AUTOSAR XML (schema 00051)
package /Components
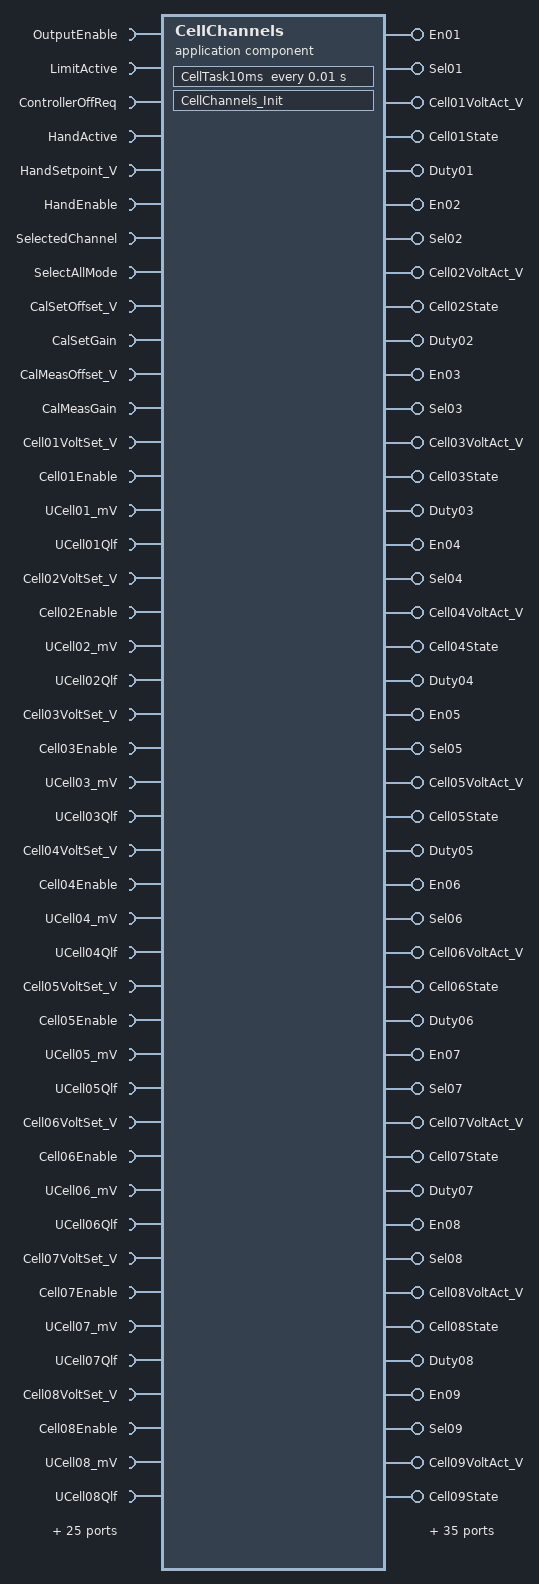
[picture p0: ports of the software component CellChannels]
  application sw component type CellChannels
    68 x require port:
      OutputEnable: nonqueued-receiver-com-spec{data-element=OutputEnable, init-value=0}, required-interface=OutputEnable
      LimitActive: nonqueued-receiver-com-spec{data-element=LimitActive, init-value=0}, required-interface=LimitActive
      ControllerOffReq: nonqueued-receiver-com-spec{data-element=ControllerOffReq, init-value=0}, required-interface=ControllerOffReq
      HandActive: nonqueued-receiver-com-spec{data-element=HandActive, init-value=0}, required-interface=HandActive
      HandSetpoint_V: nonqueued-receiver-com-spec{data-element=HandSetpoint_V, init-value=14 x 0}, required-interface=HandSetpoint_V
      HandEnable: nonqueued-receiver-com-spec{data-element=HandEnable, init-value=14 x 0}, required-interface=HandEnable
      SelectedChannel: nonqueued-receiver-com-spec{data-element=SelectedChannel, init-value=0}, required-interface=SelectedChannel
      SelectAllMode: nonqueued-receiver-com-spec{data-element=SelectAllMode, init-value=0}, required-interface=SelectAllMode
      CalSetOffset_V: nonqueued-receiver-com-spec{data-element=CalSetOffset_V, init-value=14 x 0}, required-interface=CalSetOffset_V
      CalSetGain: nonqueued-receiver-com-spec{data-element=CalSetGain, init-value=14 x 0}, required-interface=CalSetGain
      CalMeasOffset_V: nonqueued-receiver-com-spec{data-element=CalMeasOffset_V, init-value=14 x 0}, required-interface=CalMeasOffset_V
      CalMeasGain: nonqueued-receiver-com-spec{data-element=CalMeasGain, init-value=14 x 0}, required-interface=CalMeasGain
      Cell01VoltSet_V: nonqueued-receiver-com-spec{data-element=Cell01VoltSet_V, init-value=0}, required-interface=Cell01VoltSet_V
      Cell01Enable: nonqueued-receiver-com-spec{data-element=Cell01Enable, init-value=0}, required-interface=Cell01Enable
      UCell01_mV: nonqueued-receiver-com-spec{data-element=UCell01_mV, init-value=0}, required-interface=UCell01_mV
      UCell01Qlf: nonqueued-receiver-com-spec{data-element=UCell01Qlf, init-value=0}, required-interface=UCell01Qlf
      Cell02VoltSet_V: nonqueued-receiver-com-spec{data-element=Cell02VoltSet_V, init-value=0}, required-interface=Cell02VoltSet_V
      Cell02Enable: nonqueued-receiver-com-spec{data-element=Cell02Enable, init-value=0}, required-interface=Cell02Enable
      UCell02_mV: nonqueued-receiver-com-spec{data-element=UCell02_mV, init-value=0}, required-interface=UCell02_mV
      UCell02Qlf: nonqueued-receiver-com-spec{data-element=UCell02Qlf, init-value=0}, required-interface=UCell02Qlf
      Cell03VoltSet_V: nonqueued-receiver-com-spec{data-element=Cell03VoltSet_V, init-value=0}, required-interface=Cell03VoltSet_V
      Cell03Enable: nonqueued-receiver-com-spec{data-element=Cell03Enable, init-value=0}, required-interface=Cell03Enable
      UCell03_mV: nonqueued-receiver-com-spec{data-element=UCell03_mV, init-value=0}, required-interface=UCell03_mV
      UCell03Qlf: nonqueued-receiver-com-spec{data-element=UCell03Qlf, init-value=0}, required-interface=UCell03Qlf
      Cell04VoltSet_V: nonqueued-receiver-com-spec{data-element=Cell04VoltSet_V, init-value=0}, required-interface=Cell04VoltSet_V
      Cell04Enable: nonqueued-receiver-com-spec{data-element=Cell04Enable, init-value=0}, required-interface=Cell04Enable
      UCell04_mV: nonqueued-receiver-com-spec{data-element=UCell04_mV, init-value=0}, required-interface=UCell04_mV
      UCell04Qlf: nonqueued-receiver-com-spec{data-element=UCell04Qlf, init-value=0}, required-interface=UCell04Qlf
      Cell05VoltSet_V: nonqueued-receiver-com-spec{data-element=Cell05VoltSet_V, init-value=0}, required-interface=Cell05VoltSet_V
      Cell05Enable: nonqueued-receiver-com-spec{data-element=Cell05Enable, init-value=0}, required-interface=Cell05Enable
      UCell05_mV: nonqueued-receiver-com-spec{data-element=UCell05_mV, init-value=0}, required-interface=UCell05_mV
      UCell05Qlf: nonqueued-receiver-com-spec{data-element=UCell05Qlf, init-value=0}, required-interface=UCell05Qlf
      Cell06VoltSet_V: nonqueued-receiver-com-spec{data-element=Cell06VoltSet_V, init-value=0}, required-interface=Cell06VoltSet_V
      Cell06Enable: nonqueued-receiver-com-spec{data-element=Cell06Enable, init-value=0}, required-interface=Cell06Enable
      UCell06_mV: nonqueued-receiver-com-spec{data-element=UCell06_mV, init-value=0}, required-interface=UCell06_mV
      UCell06Qlf: nonqueued-receiver-com-spec{data-element=UCell06Qlf, init-value=0}, required-interface=UCell06Qlf
      Cell07VoltSet_V: nonqueued-receiver-com-spec{data-element=Cell07VoltSet_V, init-value=0}, required-interface=Cell07VoltSet_V
      Cell07Enable: nonqueued-receiver-com-spec{data-element=Cell07Enable, init-value=0}, required-interface=Cell07Enable
      UCell07_mV: nonqueued-receiver-com-spec{data-element=UCell07_mV, init-value=0}, required-interface=UCell07_mV
      UCell07Qlf: nonqueued-receiver-com-spec{data-element=UCell07Qlf, init-value=0}, required-interface=UCell07Qlf
      Cell08VoltSet_V: nonqueued-receiver-com-spec{data-element=Cell08VoltSet_V, init-value=0}, required-interface=Cell08VoltSet_V
      Cell08Enable: nonqueued-receiver-com-spec{data-element=Cell08Enable, init-value=0}, required-interface=Cell08Enable
      UCell08_mV: nonqueued-receiver-com-spec{data-element=UCell08_mV, init-value=0}, required-interface=UCell08_mV
      UCell08Qlf: nonqueued-receiver-com-spec{data-element=UCell08Qlf, init-value=0}, required-interface=UCell08Qlf
      Cell09VoltSet_V: nonqueued-receiver-com-spec{data-element=Cell09VoltSet_V, init-value=0}, required-interface=Cell09VoltSet_V
      Cell09Enable: nonqueued-receiver-com-spec{data-element=Cell09Enable, init-value=0}, required-interface=Cell09Enable
      UCell09_mV: nonqueued-receiver-com-spec{data-element=UCell09_mV, init-value=0}, required-interface=UCell09_mV
      UCell09Qlf: nonqueued-receiver-com-spec{data-element=UCell09Qlf, init-value=0}, required-interface=UCell09Qlf
      Cell10VoltSet_V: nonqueued-receiver-com-spec{data-element=Cell10VoltSet_V, init-value=0}, required-interface=Cell10VoltSet_V
      Cell10Enable: nonqueued-receiver-com-spec{data-element=Cell10Enable, init-value=0}, required-interface=Cell10Enable
      UCell10_mV: nonqueued-receiver-com-spec{data-element=UCell10_mV, init-value=0}, required-interface=UCell10_mV
      UCell10Qlf: nonqueued-receiver-com-spec{data-element=UCell10Qlf, init-value=0}, required-interface=UCell10Qlf
      Cell11VoltSet_V: nonqueued-receiver-com-spec{data-element=Cell11VoltSet_V, init-value=0}, required-interface=Cell11VoltSet_V
      Cell11Enable: nonqueued-receiver-com-spec{data-element=Cell11Enable, init-value=0}, required-interface=Cell11Enable
      UCell11_mV: nonqueued-receiver-com-spec{data-element=UCell11_mV, init-value=0}, required-interface=UCell11_mV
      UCell11Qlf: nonqueued-receiver-com-spec{data-element=UCell11Qlf, init-value=0}, required-interface=UCell11Qlf
      Cell12VoltSet_V: nonqueued-receiver-com-spec{data-element=Cell12VoltSet_V, init-value=0}, required-interface=Cell12VoltSet_V
      Cell12Enable: nonqueued-receiver-com-spec{data-element=Cell12Enable, init-value=0}, required-interface=Cell12Enable
      UCell12_mV: nonqueued-receiver-com-spec{data-element=UCell12_mV, init-value=0}, required-interface=UCell12_mV
      UCell12Qlf: nonqueued-receiver-com-spec{data-element=UCell12Qlf, init-value=0}, required-interface=UCell12Qlf
      Cell13VoltSet_V: nonqueued-receiver-com-spec{data-element=Cell13VoltSet_V, init-value=0}, required-interface=Cell13VoltSet_V
      Cell13Enable: nonqueued-receiver-com-spec{data-element=Cell13Enable, init-value=0}, required-interface=Cell13Enable
      UCell13_mV: nonqueued-receiver-com-spec{data-element=UCell13_mV, init-value=0}, required-interface=UCell13_mV
      UCell13Qlf: nonqueued-receiver-com-spec{data-element=UCell13Qlf, init-value=0}, required-interface=UCell13Qlf
      Cell14VoltSet_V: nonqueued-receiver-com-spec{data-element=Cell14VoltSet_V, init-value=0}, required-interface=Cell14VoltSet_V
      Cell14Enable: nonqueued-receiver-com-spec{data-element=Cell14Enable, init-value=0}, required-interface=Cell14Enable
      UCell14_mV: nonqueued-receiver-com-spec{data-element=UCell14_mV, init-value=0}, required-interface=UCell14_mV
      UCell14Qlf: nonqueued-receiver-com-spec{data-element=UCell14Qlf, init-value=0}, required-interface=UCell14Qlf
    79 x provide port:
      En01: nonqueued-sender-com-spec{data-element=En01, init-value=0}, provided-interface=En01
      Sel01: nonqueued-sender-com-spec{data-element=Sel01, init-value=0}, provided-interface=Sel01
      Cell01VoltAct_V: nonqueued-sender-com-spec{data-element=Cell01VoltAct_V, init-value=0}, provided-interface=Cell01VoltAct_V
      Cell01State: nonqueued-sender-com-spec{data-element=Cell01State, init-value=0}, provided-interface=Cell01State
      Duty01: nonqueued-sender-com-spec{data-element=Duty01, init-value=0}, provided-interface=Duty01
      En02: nonqueued-sender-com-spec{data-element=En02, init-value=0}, provided-interface=En02
      Sel02: nonqueued-sender-com-spec{data-element=Sel02, init-value=0}, provided-interface=Sel02
      Cell02VoltAct_V: nonqueued-sender-com-spec{data-element=Cell02VoltAct_V, init-value=0}, provided-interface=Cell02VoltAct_V
      Cell02State: nonqueued-sender-com-spec{data-element=Cell02State, init-value=0}, provided-interface=Cell02State
      Duty02: nonqueued-sender-com-spec{data-element=Duty02, init-value=0}, provided-interface=Duty02
      En03: nonqueued-sender-com-spec{data-element=En03, init-value=0}, provided-interface=En03
      Sel03: nonqueued-sender-com-spec{data-element=Sel03, init-value=0}, provided-interface=Sel03
      Cell03VoltAct_V: nonqueued-sender-com-spec{data-element=Cell03VoltAct_V, init-value=0}, provided-interface=Cell03VoltAct_V
      Cell03State: nonqueued-sender-com-spec{data-element=Cell03State, init-value=0}, provided-interface=Cell03State
      Duty03: nonqueued-sender-com-spec{data-element=Duty03, init-value=0}, provided-interface=Duty03
      En04: nonqueued-sender-com-spec{data-element=En04, init-value=0}, provided-interface=En04
      Sel04: nonqueued-sender-com-spec{data-element=Sel04, init-value=0}, provided-interface=Sel04
      Cell04VoltAct_V: nonqueued-sender-com-spec{data-element=Cell04VoltAct_V, init-value=0}, provided-interface=Cell04VoltAct_V
      Cell04State: nonqueued-sender-com-spec{data-element=Cell04State, init-value=0}, provided-interface=Cell04State
      Duty04: nonqueued-sender-com-spec{data-element=Duty04, init-value=0}, provided-interface=Duty04
      En05: nonqueued-sender-com-spec{data-element=En05, init-value=0}, provided-interface=En05
      Sel05: nonqueued-sender-com-spec{data-element=Sel05, init-value=0}, provided-interface=Sel05
      Cell05VoltAct_V: nonqueued-sender-com-spec{data-element=Cell05VoltAct_V, init-value=0}, provided-interface=Cell05VoltAct_V
      Cell05State: nonqueued-sender-com-spec{data-element=Cell05State, init-value=0}, provided-interface=Cell05State
      Duty05: nonqueued-sender-com-spec{data-element=Duty05, init-value=0}, provided-interface=Duty05
      En06: nonqueued-sender-com-spec{data-element=En06, init-value=0}, provided-interface=En06
      Sel06: nonqueued-sender-com-spec{data-element=Sel06, init-value=0}, provided-interface=Sel06
      Cell06VoltAct_V: nonqueued-sender-com-spec{data-element=Cell06VoltAct_V, init-value=0}, provided-interface=Cell06VoltAct_V
      Cell06State: nonqueued-sender-com-spec{data-element=Cell06State, init-value=0}, provided-interface=Cell06State
      Duty06: nonqueued-sender-com-spec{data-element=Duty06, init-value=0}, provided-interface=Duty06
      En07: nonqueued-sender-com-spec{data-element=En07, init-value=0}, provided-interface=En07
      Sel07: nonqueued-sender-com-spec{data-element=Sel07, init-value=0}, provided-interface=Sel07
      Cell07VoltAct_V: nonqueued-sender-com-spec{data-element=Cell07VoltAct_V, init-value=0}, provided-interface=Cell07VoltAct_V
      Cell07State: nonqueued-sender-com-spec{data-element=Cell07State, init-value=0}, provided-interface=Cell07State
      Duty07: nonqueued-sender-com-spec{data-element=Duty07, init-value=0}, provided-interface=Duty07
      En08: nonqueued-sender-com-spec{data-element=En08, init-value=0}, provided-interface=En08
      Sel08: nonqueued-sender-com-spec{data-element=Sel08, init-value=0}, provided-interface=Sel08
      Cell08VoltAct_V: nonqueued-sender-com-spec{data-element=Cell08VoltAct_V, init-value=0}, provided-interface=Cell08VoltAct_V
      Cell08State: nonqueued-sender-com-spec{data-element=Cell08State, init-value=0}, provided-interface=Cell08State
      Duty08: nonqueued-sender-com-spec{data-element=Duty08, init-value=0}, provided-interface=Duty08
      En09: nonqueued-sender-com-spec{data-element=En09, init-value=0}, provided-interface=En09
      Sel09: nonqueued-sender-com-spec{data-element=Sel09, init-value=0}, provided-interface=Sel09
      Cell09VoltAct_V: nonqueued-sender-com-spec{data-element=Cell09VoltAct_V, init-value=0}, provided-interface=Cell09VoltAct_V
      Cell09State: nonqueued-sender-com-spec{data-element=Cell09State, init-value=0}, provided-interface=Cell09State
      Duty09: nonqueued-sender-com-spec{data-element=Duty09, init-value=0}, provided-interface=Duty09
      En10: nonqueued-sender-com-spec{data-element=En10, init-value=0}, provided-interface=En10
      Sel10: nonqueued-sender-com-spec{data-element=Sel10, init-value=0}, provided-interface=Sel10
      Cell10VoltAct_V: nonqueued-sender-com-spec{data-element=Cell10VoltAct_V, init-value=0}, provided-interface=Cell10VoltAct_V
      Cell10State: nonqueued-sender-com-spec{data-element=Cell10State, init-value=0}, provided-interface=Cell10State
      Duty10: nonqueued-sender-com-spec{data-element=Duty10, init-value=0}, provided-interface=Duty10
      En11: nonqueued-sender-com-spec{data-element=En11, init-value=0}, provided-interface=En11
      Sel11: nonqueued-sender-com-spec{data-element=Sel11, init-value=0}, provided-interface=Sel11
      Cell11VoltAct_V: nonqueued-sender-com-spec{data-element=Cell11VoltAct_V, init-value=0}, provided-interface=Cell11VoltAct_V
      Cell11State: nonqueued-sender-com-spec{data-element=Cell11State, init-value=0}, provided-interface=Cell11State
      Duty11: nonqueued-sender-com-spec{data-element=Duty11, init-value=0}, provided-interface=Duty11
      En12: nonqueued-sender-com-spec{data-element=En12, init-value=0}, provided-interface=En12
      Sel12: nonqueued-sender-com-spec{data-element=Sel12, init-value=0}, provided-interface=Sel12
      Cell12VoltAct_V: nonqueued-sender-com-spec{data-element=Cell12VoltAct_V, init-value=0}, provided-interface=Cell12VoltAct_V
      Cell12State: nonqueued-sender-com-spec{data-element=Cell12State, init-value=0}, provided-interface=Cell12State
      Duty12: nonqueued-sender-com-spec{data-element=Duty12, init-value=0}, provided-interface=Duty12
      En13: nonqueued-sender-com-spec{data-element=En13, init-value=0}, provided-interface=En13
      Sel13: nonqueued-sender-com-spec{data-element=Sel13, init-value=0}, provided-interface=Sel13
      Cell13VoltAct_V: nonqueued-sender-com-spec{data-element=Cell13VoltAct_V, init-value=0}, provided-interface=Cell13VoltAct_V
      Cell13State: nonqueued-sender-com-spec{data-element=Cell13State, init-value=0}, provided-interface=Cell13State
      Duty13: nonqueued-sender-com-spec{data-element=Duty13, init-value=0}, provided-interface=Duty13
      En14: nonqueued-sender-com-spec{data-element=En14, init-value=0}, provided-interface=En14
      Sel14: nonqueued-sender-com-spec{data-element=Sel14, init-value=0}, provided-interface=Sel14
      Cell14VoltAct_V: nonqueued-sender-com-spec{data-element=Cell14VoltAct_V, init-value=0}, provided-interface=Cell14VoltAct_V
      Cell14State: nonqueued-sender-com-spec{data-element=Cell14State, init-value=0}, provided-interface=Cell14State
      Duty14: nonqueued-sender-com-spec{data-element=Duty14, init-value=0}, provided-interface=Duty14
      ActualVolt_V: nonqueued-sender-com-spec{data-element=ActualVolt_V, init-value=14 x 0}, provided-interface=ActualVolt_V
      ControllerOn: nonqueued-sender-com-spec{data-element=ControllerOn, init-value=0}, provided-interface=ControllerOn
      ControllerOffAct: nonqueued-sender-com-spec{data-element=ControllerOffAct, init-value=0}, provided-interface=ControllerOffAct
      ChannelsReleased: nonqueued-sender-com-spec{data-element=ChannelsReleased, init-value=0}, provided-interface=ChannelsReleased
      OverVoltage: nonqueued-sender-com-spec{data-element=OverVoltage, init-value=0}, provided-interface=OverVoltage
      Cell15State: nonqueued-sender-com-spec{data-element=Cell15State, init-value=0}, provided-interface=Cell15State
      Cell15VoltAct_V: nonqueued-sender-com-spec{data-element=Cell15VoltAct_V, init-value=0}, provided-interface=Cell15VoltAct_V
      Cell16State: nonqueued-sender-com-spec{data-element=Cell16State, init-value=0}, provided-interface=Cell16State
      Cell16VoltAct_V: nonqueued-sender-com-spec{data-element=Cell16VoltAct_V, init-value=0}, provided-interface=Cell16VoltAct_V
    require port CalPrm: required-interface=CalPrm
      required-com-specs:
        init-value=CalPrm_CtrlKi_per_s:1, parameter=CtrlKi_per_s
        init-value=CalPrm_CtrlKp:0.2, parameter=CtrlKp
        init-value=CalPrm_CtrlLimit_V:0.1, parameter=CtrlLimit_V
        init-value=CalPrm_OutputFloor_V:0.7, parameter=OutputFloor_V
        init-value=CalPrm_OverVoltThd_V:0.2, parameter=OverVoltThd_V
        init-value=CalPrm_SetpointLimit_V:5, parameter=SetpointLimit_V
        init-value=CalPrm_StepThreshold_V:0.2, parameter=StepThreshold_V
        init-value=CalPrm_VoltageSenseFilter:0.1, parameter=VoltageSenseFilter
        init-value=CalPrm_VoltageSenseMeas_Ax:[CalPrm_VoltageSenseMeas_Ax_rt_Array_float32_6_1:0, CalPrm_VoltageSenseMeas_Ax_rt_Array_float32_6_2:398.1, CalPrm_VoltageSenseMeas_Ax_rt_Array_float32_6_3:795.7, CalPrm_VoltageSenseMeas_Ax_rt_Array_float32_6_4:1195.8, CalPrm_VoltageSenseMeas_Ax_rt_Array_float32_6_5:1596.4, CalPrm_VoltageSenseMeas_Ax_rt_Array_float32_6_6:1996], parameter=VoltageSenseMeas_Ax
        init-value=CalPrm_VoltageSenseValue_T:[CalPrm_VoltageSenseValue_T_rt_Array_float32_6_1:0, CalPrm_VoltageSenseValue_T_rt_Array_float32_6_2:1, CalPrm_VoltageSenseValue_T_rt_Array_float32_6_3:2, CalPrm_VoltageSenseValue_T_rt_Array_float32_6_4:3, CalPrm_VoltageSenseValue_T_rt_Array_float32_6_5:4, CalPrm_VoltageSenseValue_T_rt_Array_float32_6_6:5], parameter=VoltageSenseValue_T
        init-value=CalPrm_VoltageSetPwm_T:[CalPrm_VoltageSetPwm_T_rt_Array_float32_6_1:0, CalPrm_VoltageSetPwm_T_rt_Array_float32_6_2:0.185875, CalPrm_VoltageSetPwm_T_rt_Array_float32_6_3:0.378085, CalPrm_VoltageSetPwm_T_rt_Array_float32_6_4:0.570892, CalPrm_VoltageSetPwm_T_rt_Array_float32_6_5:0.763797, CalPrm_VoltageSetPwm_T_rt_Array_float32_6_6:0.9566], parameter=VoltageSetPwm_T
        init-value=CalPrm_VoltageSetValue_Ax:[CalPrm_VoltageSetValue_Ax_rt_Array_float32_6_1:0, CalPrm_VoltageSetValue_Ax_rt_Array_float32_6_2:1, CalPrm_VoltageSetValue_Ax_rt_Array_float32_6_3:2, CalPrm_VoltageSetValue_Ax_rt_Array_float32_6_4:3, CalPrm_VoltageSetValue_Ax_rt_Array_float32_6_5:4, CalPrm_VoltageSetValue_Ax_rt_Array_float32_6_6:5], parameter=VoltageSetValue_Ax
        init-value=CalPrm_OverVoltTime_cycles:10, parameter=OverVoltTime_cycles
        init-value=CalPrm_StepHold_cycles:50, parameter=StepHold_cycles
    behavior CellChannels_IB: handle-termination-and-restart=NO-SUPPORT
      timing event Event_CellTask10ms: start-on-event=CellTask10ms, period=0.01
      runnable CellChannels_Init
        data-send-points:
          access OUT_Cell15State_Cell15State: accessed-variable=Cell15State.Cell15State
          access OUT_Cell16State_Cell16State: accessed-variable=Cell16State.Cell16State
      runnable CellTask10ms
        data-receive-point-by-arguments:
          68 x access:
            IN_CalMeasGain_CalMeasGain: accessed-variable=CalMeasGain.CalMeasGain
            IN_CalMeasOffset_V_CalMeasOffset_V: accessed-variable=CalMeasOffset_V.CalMeasOffset_V
            IN_CalSetGain_CalSetGain: accessed-variable=CalSetGain.CalSetGain
            IN_CalSetOffset_V_CalSetOffset_V: accessed-variable=CalSetOffset_V.CalSetOffset_V
            IN_Cell01Enable_Cell01Enable: accessed-variable=Cell01Enable.Cell01Enable
            IN_Cell01VoltSet_V_Cell01VoltSet_V: accessed-variable=Cell01VoltSet_V.Cell01VoltSet_V
            IN_Cell02Enable_Cell02Enable: accessed-variable=Cell02Enable.Cell02Enable
            IN_Cell02VoltSet_V_Cell02VoltSet_V: accessed-variable=Cell02VoltSet_V.Cell02VoltSet_V
            IN_Cell03Enable_Cell03Enable: accessed-variable=Cell03Enable.Cell03Enable
            IN_Cell03VoltSet_V_Cell03VoltSet_V: accessed-variable=Cell03VoltSet_V.Cell03VoltSet_V
            IN_Cell04Enable_Cell04Enable: accessed-variable=Cell04Enable.Cell04Enable
            IN_Cell04VoltSet_V_Cell04VoltSet_V: accessed-variable=Cell04VoltSet_V.Cell04VoltSet_V
            IN_Cell05Enable_Cell05Enable: accessed-variable=Cell05Enable.Cell05Enable
            IN_Cell05VoltSet_V_Cell05VoltSet_V: accessed-variable=Cell05VoltSet_V.Cell05VoltSet_V
            IN_Cell06Enable_Cell06Enable: accessed-variable=Cell06Enable.Cell06Enable
            IN_Cell06VoltSet_V_Cell06VoltSet_V: accessed-variable=Cell06VoltSet_V.Cell06VoltSet_V
            IN_Cell07Enable_Cell07Enable: accessed-variable=Cell07Enable.Cell07Enable
            IN_Cell07VoltSet_V_Cell07VoltSet_V: accessed-variable=Cell07VoltSet_V.Cell07VoltSet_V
            IN_Cell08Enable_Cell08Enable: accessed-variable=Cell08Enable.Cell08Enable
            IN_Cell08VoltSet_V_Cell08VoltSet_V: accessed-variable=Cell08VoltSet_V.Cell08VoltSet_V
            IN_Cell09Enable_Cell09Enable: accessed-variable=Cell09Enable.Cell09Enable
            IN_Cell09VoltSet_V_Cell09VoltSet_V: accessed-variable=Cell09VoltSet_V.Cell09VoltSet_V
            IN_Cell10Enable_Cell10Enable: accessed-variable=Cell10Enable.Cell10Enable
            IN_Cell10VoltSet_V_Cell10VoltSet_V: accessed-variable=Cell10VoltSet_V.Cell10VoltSet_V
            IN_Cell11Enable_Cell11Enable: accessed-variable=Cell11Enable.Cell11Enable
            IN_Cell11VoltSet_V_Cell11VoltSet_V: accessed-variable=Cell11VoltSet_V.Cell11VoltSet_V
            IN_Cell12Enable_Cell12Enable: accessed-variable=Cell12Enable.Cell12Enable
            IN_Cell12VoltSet_V_Cell12VoltSet_V: accessed-variable=Cell12VoltSet_V.Cell12VoltSet_V
            IN_Cell13Enable_Cell13Enable: accessed-variable=Cell13Enable.Cell13Enable
            IN_Cell13VoltSet_V_Cell13VoltSet_V: accessed-variable=Cell13VoltSet_V.Cell13VoltSet_V
            IN_Cell14Enable_Cell14Enable: accessed-variable=Cell14Enable.Cell14Enable
            IN_Cell14VoltSet_V_Cell14VoltSet_V: accessed-variable=Cell14VoltSet_V.Cell14VoltSet_V
            IN_ControllerOffReq_ControllerOffReq: accessed-variable=ControllerOffReq.ControllerOffReq
            IN_HandActive_HandActive: accessed-variable=HandActive.HandActive
            IN_HandEnable_HandEnable: accessed-variable=HandEnable.HandEnable
            IN_HandSetpoint_V_HandSetpoint_V: accessed-variable=HandSetpoint_V.HandSetpoint_V
            IN_LimitActive_LimitActive: accessed-variable=LimitActive.LimitActive
            IN_OutputEnable_OutputEnable: accessed-variable=OutputEnable.OutputEnable
            IN_SelectAllMode_SelectAllMode: accessed-variable=SelectAllMode.SelectAllMode
            IN_SelectedChannel_SelectedChannel: accessed-variable=SelectedChannel.SelectedChannel
            IN_UCell01Qlf_UCell01Qlf: accessed-variable=UCell01Qlf.UCell01Qlf
            IN_UCell01_mV_UCell01_mV: accessed-variable=UCell01_mV.UCell01_mV
            IN_UCell02Qlf_UCell02Qlf: accessed-variable=UCell02Qlf.UCell02Qlf
            IN_UCell02_mV_UCell02_mV: accessed-variable=UCell02_mV.UCell02_mV
            IN_UCell03Qlf_UCell03Qlf: accessed-variable=UCell03Qlf.UCell03Qlf
            IN_UCell03_mV_UCell03_mV: accessed-variable=UCell03_mV.UCell03_mV
            IN_UCell04Qlf_UCell04Qlf: accessed-variable=UCell04Qlf.UCell04Qlf
            IN_UCell04_mV_UCell04_mV: accessed-variable=UCell04_mV.UCell04_mV
            IN_UCell05Qlf_UCell05Qlf: accessed-variable=UCell05Qlf.UCell05Qlf
            IN_UCell05_mV_UCell05_mV: accessed-variable=UCell05_mV.UCell05_mV
            IN_UCell06Qlf_UCell06Qlf: accessed-variable=UCell06Qlf.UCell06Qlf
            IN_UCell06_mV_UCell06_mV: accessed-variable=UCell06_mV.UCell06_mV
            IN_UCell07Qlf_UCell07Qlf: accessed-variable=UCell07Qlf.UCell07Qlf
            IN_UCell07_mV_UCell07_mV: accessed-variable=UCell07_mV.UCell07_mV
            IN_UCell08Qlf_UCell08Qlf: accessed-variable=UCell08Qlf.UCell08Qlf
            IN_UCell08_mV_UCell08_mV: accessed-variable=UCell08_mV.UCell08_mV
            IN_UCell09Qlf_UCell09Qlf: accessed-variable=UCell09Qlf.UCell09Qlf
            IN_UCell09_mV_UCell09_mV: accessed-variable=UCell09_mV.UCell09_mV
            IN_UCell10Qlf_UCell10Qlf: accessed-variable=UCell10Qlf.UCell10Qlf
            IN_UCell10_mV_UCell10_mV: accessed-variable=UCell10_mV.UCell10_mV
            IN_UCell11Qlf_UCell11Qlf: accessed-variable=UCell11Qlf.UCell11Qlf
            IN_UCell11_mV_UCell11_mV: accessed-variable=UCell11_mV.UCell11_mV
            IN_UCell12Qlf_UCell12Qlf: accessed-variable=UCell12Qlf.UCell12Qlf
            IN_UCell12_mV_UCell12_mV: accessed-variable=UCell12_mV.UCell12_mV
            IN_UCell13Qlf_UCell13Qlf: accessed-variable=UCell13Qlf.UCell13Qlf
            IN_UCell13_mV_UCell13_mV: accessed-variable=UCell13_mV.UCell13_mV
            IN_UCell14Qlf_UCell14Qlf: accessed-variable=UCell14Qlf.UCell14Qlf
            IN_UCell14_mV_UCell14_mV: accessed-variable=UCell14_mV.UCell14_mV
        data-send-points:
          79 x access:
            OUT_En01_En01: accessed-variable=En01.En01
            OUT_Sel01_Sel01: accessed-variable=Sel01.Sel01
            OUT_Cell01VoltAct_V_Cell01VoltAct_V: accessed-variable=Cell01VoltAct_V.Cell01VoltAct_V
            OUT_Cell01State_Cell01State: accessed-variable=Cell01State.Cell01State
            OUT_Duty01_Duty01: accessed-variable=Duty01.Duty01
            OUT_En02_En02: accessed-variable=En02.En02
            OUT_Sel02_Sel02: accessed-variable=Sel02.Sel02
            OUT_Cell02VoltAct_V_Cell02VoltAct_V: accessed-variable=Cell02VoltAct_V.Cell02VoltAct_V
            OUT_Cell02State_Cell02State: accessed-variable=Cell02State.Cell02State
            OUT_Duty02_Duty02: accessed-variable=Duty02.Duty02
            OUT_En03_En03: accessed-variable=En03.En03
            OUT_Sel03_Sel03: accessed-variable=Sel03.Sel03
            OUT_Cell03VoltAct_V_Cell03VoltAct_V: accessed-variable=Cell03VoltAct_V.Cell03VoltAct_V
            OUT_Cell03State_Cell03State: accessed-variable=Cell03State.Cell03State
            OUT_Duty03_Duty03: accessed-variable=Duty03.Duty03
            OUT_En04_En04: accessed-variable=En04.En04
            OUT_Sel04_Sel04: accessed-variable=Sel04.Sel04
            OUT_Cell04VoltAct_V_Cell04VoltAct_V: accessed-variable=Cell04VoltAct_V.Cell04VoltAct_V
            OUT_Cell04State_Cell04State: accessed-variable=Cell04State.Cell04State
            OUT_Duty04_Duty04: accessed-variable=Duty04.Duty04
            OUT_En05_En05: accessed-variable=En05.En05
            OUT_Sel05_Sel05: accessed-variable=Sel05.Sel05
            OUT_Cell05VoltAct_V_Cell05VoltAct_V: accessed-variable=Cell05VoltAct_V.Cell05VoltAct_V
            OUT_Cell05State_Cell05State: accessed-variable=Cell05State.Cell05State
            OUT_Duty05_Duty05: accessed-variable=Duty05.Duty05
            OUT_En06_En06: accessed-variable=En06.En06
            OUT_Sel06_Sel06: accessed-variable=Sel06.Sel06
            OUT_Cell06VoltAct_V_Cell06VoltAct_V: accessed-variable=Cell06VoltAct_V.Cell06VoltAct_V
            OUT_Cell06State_Cell06State: accessed-variable=Cell06State.Cell06State
            OUT_Duty06_Duty06: accessed-variable=Duty06.Duty06
            OUT_En07_En07: accessed-variable=En07.En07
            OUT_Sel07_Sel07: accessed-variable=Sel07.Sel07
            OUT_Cell07VoltAct_V_Cell07VoltAct_V: accessed-variable=Cell07VoltAct_V.Cell07VoltAct_V
            OUT_Cell07State_Cell07State: accessed-variable=Cell07State.Cell07State
            OUT_Duty07_Duty07: accessed-variable=Duty07.Duty07
            OUT_En08_En08: accessed-variable=En08.En08
            OUT_Sel08_Sel08: accessed-variable=Sel08.Sel08
            OUT_Cell08VoltAct_V_Cell08VoltAct_V: accessed-variable=Cell08VoltAct_V.Cell08VoltAct_V
            OUT_Cell08State_Cell08State: accessed-variable=Cell08State.Cell08State
            OUT_Duty08_Duty08: accessed-variable=Duty08.Duty08
            OUT_En09_En09: accessed-variable=En09.En09
            OUT_Sel09_Sel09: accessed-variable=Sel09.Sel09
            OUT_Cell09VoltAct_V_Cell09VoltAct_V: accessed-variable=Cell09VoltAct_V.Cell09VoltAct_V
            OUT_Cell09State_Cell09State: accessed-variable=Cell09State.Cell09State
            OUT_Duty09_Duty09: accessed-variable=Duty09.Duty09
            OUT_En10_En10: accessed-variable=En10.En10
            OUT_Sel10_Sel10: accessed-variable=Sel10.Sel10
            OUT_Cell10VoltAct_V_Cell10VoltAct_V: accessed-variable=Cell10VoltAct_V.Cell10VoltAct_V
            OUT_Cell10State_Cell10State: accessed-variable=Cell10State.Cell10State
            OUT_Duty10_Duty10: accessed-variable=Duty10.Duty10
            OUT_En11_En11: accessed-variable=En11.En11
            OUT_Sel11_Sel11: accessed-variable=Sel11.Sel11
            OUT_Cell11VoltAct_V_Cell11VoltAct_V: accessed-variable=Cell11VoltAct_V.Cell11VoltAct_V
            OUT_Cell11State_Cell11State: accessed-variable=Cell11State.Cell11State
            OUT_Duty11_Duty11: accessed-variable=Duty11.Duty11
            OUT_En12_En12: accessed-variable=En12.En12
            OUT_Sel12_Sel12: accessed-variable=Sel12.Sel12
            OUT_Cell12VoltAct_V_Cell12VoltAct_V: accessed-variable=Cell12VoltAct_V.Cell12VoltAct_V
            OUT_Cell12State_Cell12State: accessed-variable=Cell12State.Cell12State
            OUT_Duty12_Duty12: accessed-variable=Duty12.Duty12
            OUT_En13_En13: accessed-variable=En13.En13
            OUT_Sel13_Sel13: accessed-variable=Sel13.Sel13
            OUT_Cell13VoltAct_V_Cell13VoltAct_V: accessed-variable=Cell13VoltAct_V.Cell13VoltAct_V
            OUT_Cell13State_Cell13State: accessed-variable=Cell13State.Cell13State
            OUT_Duty13_Duty13: accessed-variable=Duty13.Duty13
            OUT_En14_En14: accessed-variable=En14.En14
            OUT_Sel14_Sel14: accessed-variable=Sel14.Sel14
            OUT_Cell14VoltAct_V_Cell14VoltAct_V: accessed-variable=Cell14VoltAct_V.Cell14VoltAct_V
            OUT_Cell14State_Cell14State: accessed-variable=Cell14State.Cell14State
            OUT_Duty14_Duty14: accessed-variable=Duty14.Duty14
            OUT_ActualVolt_V_ActualVolt_V: accessed-variable=ActualVolt_V.ActualVolt_V
            OUT_ControllerOn_ControllerOn: accessed-variable=ControllerOn.ControllerOn
            OUT_ControllerOffAct_ControllerOffAct: accessed-variable=ControllerOffAct.ControllerOffAct
            OUT_ChannelsReleased_ChannelsReleased: accessed-variable=ChannelsReleased.ChannelsReleased
            OUT_OverVoltage_OverVoltage: accessed-variable=OverVoltage.OverVoltage
            OUT_Cell15State_Cell15State: accessed-variable=Cell15State.Cell15State
            OUT_Cell15VoltAct_V_Cell15VoltAct_V: accessed-variable=Cell15VoltAct_V.Cell15VoltAct_V
            OUT_Cell16State_Cell16State: accessed-variable=Cell16State.Cell16State
            OUT_Cell16VoltAct_V_Cell16VoltAct_V: accessed-variable=Cell16VoltAct_V.Cell16VoltAct_V
        14 x parameter access:
          CALPRM_CalPrm_CtrlKi_per_s: accessed-parameter=CalPrm.CtrlKi_per_s
          CALPRM_CalPrm_CtrlKp: accessed-parameter=CalPrm.CtrlKp
          CALPRM_CalPrm_CtrlLimit_V: accessed-parameter=CalPrm.CtrlLimit_V
          CALPRM_CalPrm_OutputFloor_V: accessed-parameter=CalPrm.OutputFloor_V
          CALPRM_CalPrm_OverVoltThd_V: accessed-parameter=CalPrm.OverVoltThd_V
          CALPRM_CalPrm_OverVoltTime_cycles: accessed-parameter=CalPrm.OverVoltTime_cycles
          CALPRM_CalPrm_SetpointLimit_V: accessed-parameter=CalPrm.SetpointLimit_V
          CALPRM_CalPrm_StepHold_cycles: accessed-parameter=CalPrm.StepHold_cycles
          CALPRM_CalPrm_StepThreshold_V: accessed-parameter=CalPrm.StepThreshold_V
          CALPRM_CalPrm_VoltageSenseFilter: accessed-parameter=CalPrm.VoltageSenseFilter
          CALPRM_CalPrm_VoltageSenseMeas_Ax: accessed-parameter=CalPrm.VoltageSenseMeas_Ax
          CALPRM_CalPrm_VoltageSenseValue_T: accessed-parameter=CalPrm.VoltageSenseValue_T
          CALPRM_CalPrm_VoltageSetPwm_T: accessed-parameter=CalPrm.VoltageSetPwm_T
          CALPRM_CalPrm_VoltageSetValue_Ax: accessed-parameter=CalPrm.VoltageSetValue_Ax
      variation point proxy CellCount: category=VALUE, value-access=integer-value-variation-point=CellCount
